# MSP432P411Y register map
Vendor: Texas Instruments; File version: 3.230
Registers are 32-bit, read-write, reset 0x0 unless marked. A register's access mark holds for its fields unless they carry their own. Offsets are from the block's base; [hi:lo] are bit positions.

## EUSCI_A0
Base 0x40001000
Same registers: EUSCI_A1 0x40001400, EUSCI_A2 0x40001800, EUSCI_A3 0x40001C00
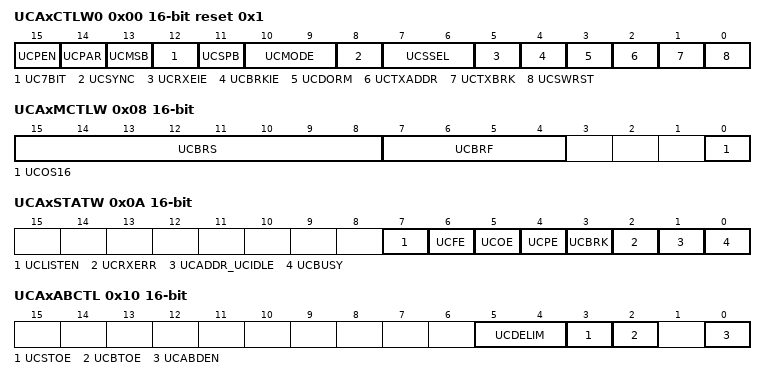
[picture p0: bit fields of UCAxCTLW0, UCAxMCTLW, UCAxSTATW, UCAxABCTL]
0x00 UCAxCTLW0 16-bit reset 0x1 — eUSCI_Ax Control Word Register 0
  [15] UCPEN — Parity enable
    0=Parity disabled; 1=Parity enabled. Parity bit is generated (UCAxTXD) and expected (UCAxRXD). In address-bit multiprocessor mode, the address bit is included in the parity calculation.
  [14] UCPAR — Parity select
    0=Odd parity; 1=Even parity
  [13] UCMSB — MSB first select
    0=LSB first; 1=MSB first
  [12] UC7BIT — Character length
    0=8-bit data; 1=7-bit data
  [11] UCSPB — Stop bit select
    0=One stop bit; 1=Two stop bits
  [10:9] UCMODE — eUSCI_A mode
    0=UART mode; 1=Idle-line multiprocessor mode; 2=Address-bit multiprocessor mode; 3=UART mode with automatic baud-rate detection
  [8] UCSYNC — Synchronous mode enable
    0=Asynchronous mode; 1=Synchronous mode
  [7:6] UCSSEL — eUSCI_A clock source select
    0=UCLK; 1=ACLK; 2=SMCLK
  [5] UCRXEIE — Receive erroneous-character interrupt enable
    0=Erroneous characters rejected and UCRXIFG is not set; 1=Erroneous characters received set UCRXIFG
  [4] UCBRKIE — Receive break character interrupt enable
    0=Received break characters do not set UCRXIFG; 1=Received break characters set UCRXIFG
  [3] UCDORM — Dormant
    0=Not dormant. All received characters set UCRXIFG.; 1=Dormant. Only characters that are preceded by an idle-line or with address bit set UCRXIFG. In UART mode with automatic baud-rate detection, only the combination of a break and synch field sets UCRXIFG.
  [2] UCTXADDR — Transmit address
    0=Next frame transmitted is data; 1=Next frame transmitted is an address
  [1] UCTXBRK — Transmit break
    0=Next frame transmitted is not a break; 1=Next frame transmitted is a break or a break/synch
  [0] UCSWRST — Software reset enable
    0=Disabled. eUSCI_A reset released for operation; 1=Enabled. eUSCI_A logic held in reset state
0x02 UCAxCTLW1 16-bit reset 0x3 — eUSCI_Ax Control Word Register 1
  [1:0] UCGLIT — Deglitch time
    0=Approximately 2 ns (equivalent of 1 delay element); 1=Approximately 50 ns; 2=Approximately 100 ns; 3=Approximately 200 ns
0x06 UCAxBRW 16-bit (reset mask 0xFF) — eUSCI_Ax Baud Rate Control Word Register
  [15:0] UCBR — Clock prescaler setting of the Baud rate generator
0x08 UCAxMCTLW 16-bit — eUSCI_Ax Modulation Control Word Register
  [15:8] UCBRS — Second modulation stage select
  [7:4] UCBRF — First modulation stage select
  [0] UCOS16 — Oversampling mode enabled
    0=Disabled; 1=Enabled
0x0A UCAxSTATW 16-bit — eUSCI_Ax Status Register
  [7] UCLISTEN — Listen enable
    0=Disabled; 1=Enabled. UCAxTXD is internally fed back to the receiver
  [6] UCFE — Framing error flag
    0=No error; 1=Character received with low stop bit
  [5] UCOE — Overrun error flag
    0=No error; 1=Overrun error occurred
  [4] UCPE — Parity error flag. When UCPEN = 0, UCPE is read as 0. UCPE is cleared when UCAxRXBUF is read.
    0=No error; 1=Character received with parity error
  [3] UCBRK — Break detect flag
    0=No break condition; 1=Break condition occurred
  [2] UCRXERR — Receive error flag
    0=No receive errors detected; 1=Receive error detected
  [1] UCADDR_UCIDLE — Address received / Idle line detected
  [0] UCBUSY ro — eUSCI_A busy
    on read: 0=eUSCI_A inactive; 1=eUSCI_A transmitting or receiving
0x0C UCAxRXBUF 16-bit ro — eUSCI_Ax Receive Buffer Register
  [7:0] UCRXBUF — Receive data buffer
0x0E UCAxTXBUF 16-bit — eUSCI_Ax Transmit Buffer Register
  [7:0] UCTXBUF — Transmit data buffer
0x10 UCAxABCTL 16-bit — eUSCI_Ax Auto Baud Rate Control Register
  [5:4] UCDELIM — Break/synch delimiter length
    0=1 bit time; 1=2 bit times; 2=3 bit times; 3=4 bit times
  [3] UCSTOE — Synch field time out error
    0=No error; 1=Length of synch field exceeded measurable time
  [2] UCBTOE — Break time out error
    0=No error; 1=Length of break field exceeded 22 bit times
  [0] UCABDEN — Automatic baud-rate detect enable
    0=Baud-rate detection disabled. Length of break and synch field is not measured.; 1=Baud-rate detection enabled. Length of break and synch field is measured and baud-rate settings are changed accordingly.
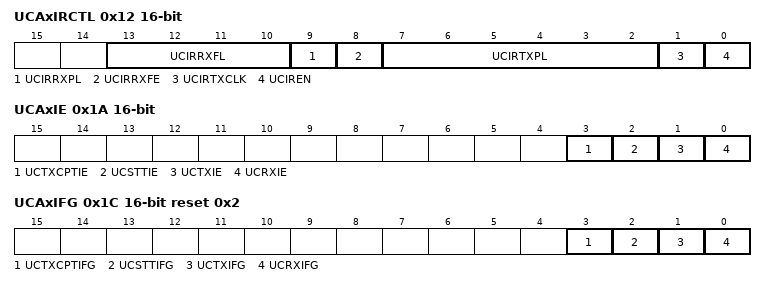
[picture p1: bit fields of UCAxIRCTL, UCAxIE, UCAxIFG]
0x12 UCAxIRCTL 16-bit — eUSCI_Ax IrDA Control Word Register
  [13:10] UCIRRXFL — Receive filter length
  [9] UCIRRXPL — IrDA receive input UCAxRXD polarity
    0=IrDA transceiver delivers a high pulse when a light pulse is seen; 1=IrDA transceiver delivers a low pulse when a light pulse is seen
  [8] UCIRRXFE — IrDA receive filter enabled
    0=Receive filter disabled; 1=Receive filter enabled
  [7:2] UCIRTXPL — Transmit pulse length
  [1] UCIRTXCLK — IrDA transmit pulse clock select
    0=BRCLK; 1=BITCLK16 when UCOS16 = 1. Otherwise, BRCLK.
  [0] UCIREN — IrDA encoder/decoder enable
    0=IrDA encoder/decoder disabled; 1=IrDA encoder/decoder enabled
0x1A UCAxIE 16-bit — eUSCI_Ax Interrupt Enable Register
  [all] fields
    0=Interrupt disabled; 1=Interrupt enabled
  [3] UCTXCPTIE — Transmit complete interrupt enable
  [2] UCSTTIE — Start bit interrupt enable
  [1] UCTXIE — Transmit interrupt enable
  [0] UCRXIE — Receive interrupt enable
0x1C UCAxIFG 16-bit reset 0x2 — eUSCI_Ax Interrupt Flag Register
  [all] fields
    0=No interrupt pending; 1=Interrupt pending
  [3] UCTXCPTIFG — Transmit ready interrupt enable
  [2] UCSTTIFG — Start bit interrupt flag
  [1] UCTXIFG — Transmit interrupt flag
  [0] UCRXIFG — Receive interrupt flag
0x1E UCAxIV 16-bit ro — eUSCI_Ax Interrupt Vector Register
  [15:0] UCIV — eUSCI_A interrupt vector value
    on read: 0=No interrupt pending; 2=Interrupt Source: Receive buffer full; Interrupt Flag: UCRXIFG; Interrupt Priority: Highest; 4=Interrupt Source: Transmit buffer empty; Interrupt Flag: UCTXIFG; 6=Interrupt Source: Start bit received; Interrupt Flag: UCSTTIFG; 8=Interrupt Source: Transmit complete; Interrupt Flag: UCTXCPTIFG; Interrupt Priority: Lowest

## Notices in the file
Copyright (C) 2012-2018 Texas Instruments Incorporated - http://www.ti.com
Redistribution and use in source and binary forms, with or without
modification, are permitted provided that the following conditions
are met:
Redistributions of source code must retain the above copyright
notice, this list of conditions and the following disclaimer.
Redistributions in binary form must reproduce the above copyright
notice, this list of conditions and the following disclaimer in the
documentation and/or other materials provided with the
distribution.
Neither the name of Texas Instruments Incorporated nor the names of
its contributors may be used to endorse or promote products derived
from this software without specific prior written permission.
THIS SOFTWARE IS PROVIDED BY THE COPYRIGHT HOLDERS AND CONTRIBUTORS
"AS IS" AND ANY EXPRESS OR IMPLIED WARRANTIES, INCLUDING, BUT NOT
LIMITED TO, THE IMPLIED WARRANTIES OF MERCHANTABILITY AND FITNESS FOR
A PARTICULAR PURPOSE ARE DISCLAIMED. IN NO EVENT SHALL THE COPYRIGHT
OWNER OR CONTRIBUTORS BE LIABLE FOR ANY DIRECT, INDIRECT, INCIDENTAL,
SPECIAL, EXEMPLARY, OR CONSEQUENTIAL DAMAGES (INCLUDING, BUT NOT
LIMITED TO, PROCUREMENT OF SUBSTITUTE GOODS OR SERVICES; LOSS OF USE,
DATA, OR PROFITS; OR BUSINESS INTERRUPTION) HOWEVER CAUSED AND ON ANY
THEORY OF LIABILITY, WHETHER IN CONTRACT, STRICT LIABILITY, OR TORT
(INCLUDING NEGLIGENCE OR OTHERWISE) ARISING IN ANY WAY OUT OF THE USE
OF THIS SOFTWARE, EVEN IF ADVISED OF THE POSSIBILITY OF SUCH DAMAGE.
